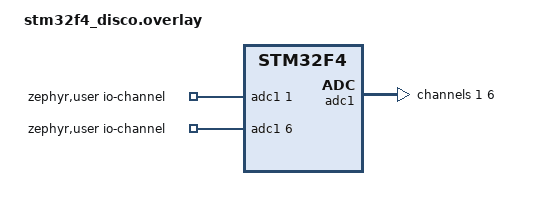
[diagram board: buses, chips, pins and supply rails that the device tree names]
/*
 * Copyright (c) 2025 Ajith Anandhan
 *
 * SPDX-License-Identifier: Apache-2.0
 */

/ {
	zephyr,user {
		io-channels = <&adc1 1>, <&adc1 6>;
	};
};

&adc1 {
	#address-cells = <1>;
	#size-cells = <0>;

	channel@1 {
		reg = <1>;
		zephyr,gain = "ADC_GAIN_1";
		zephyr,reference = "ADC_REF_INTERNAL";
		zephyr,acquisition-time = <ADC_ACQ_TIME_DEFAULT>;
		zephyr,resolution = <12>;
	};

	channel@6 {
		reg = <6>;
		zephyr,gain = "ADC_GAIN_1";
		zephyr,reference = "ADC_REF_INTERNAL";
		zephyr,acquisition-time = <ADC_ACQ_TIME_DEFAULT>;
		zephyr,resolution = <12>;
	};
};
